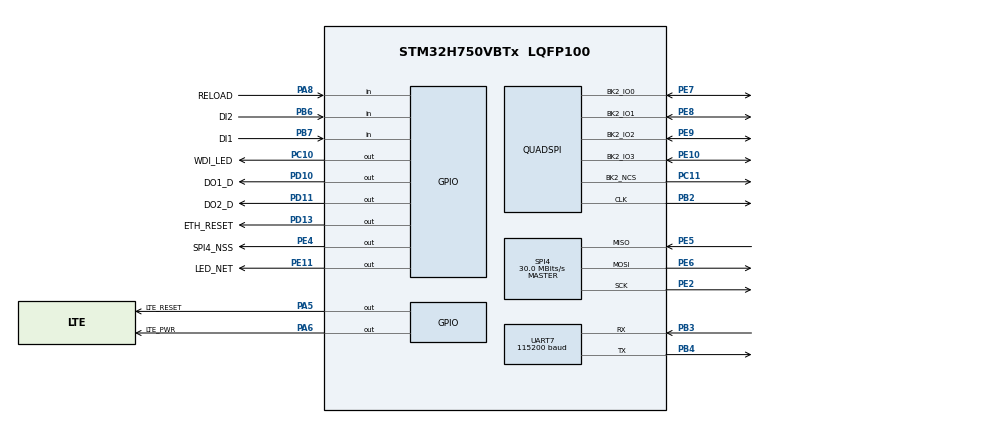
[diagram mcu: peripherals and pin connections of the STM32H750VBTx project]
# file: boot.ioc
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CORTEX_M7.AccessPermission_S-Cortex_Memory_Protection_Unit_Region1_Settings_S=MPU_REGION_PRIV_RO_URO
CORTEX_M7.BaseAddress_S-Cortex_Memory_Protection_Unit_Region1_Settings_S=0x90000000
CORTEX_M7.DisableExec_S-Cortex_Memory_Protection_Unit_Region1_Settings_S=MPU_INSTRUCTION_ACCESS_ENABLE
CORTEX_M7.Enable_S-Cortex_Memory_Protection_Unit_Region1_Settings_S=MPU_REGION_ENABLE
CORTEX_M7.IsBufferable_S-Cortex_Memory_Protection_Unit_Region1_Settings_S=MPU_ACCESS_NOT_BUFFERABLE
CORTEX_M7.IsCacheable_S-Cortex_Memory_Protection_Unit_Region1_Settings_S=MPU_ACCESS_CACHEABLE
CORTEX_M7.IsShareable_S-Cortex_Memory_Protection_Unit_Region1_Settings_S=MPU_ACCESS_NOT_SHAREABLE
CORTEX_M7.MPU_Control=MPU_PRIVILEGED_DEFAULT
CORTEX_M7.Size_S-Cortex_Memory_Protection_Unit_Region1_Settings_S=MPU_REGION_SIZE_4MB
CORTEX_M7.SubRegionDisable_S-Cortex_Memory_Protection_Unit_Region1_Settings_S=0x0
CORTEX_M7.TypeExtField_S-Cortex_Memory_Protection_Unit_Region1_Settings_S=MPU_TEX_LEVEL0
CORTEX_M7.default_mode_Activation=1
IWDG1.Prescaler=IWDG_PRESCALER_32
IWDG1.Reload=1600
Mcu.Family=STM32H7
Mcu.Name=STM32H750VBTx
Mcu.Package=LQFP100
NVIC.PriorityGroup=NVIC_PRIORITYGROUP_4
PA13\ (JTMS/SWDIO).Mode=Serial_Wire
PA13\ (JTMS/SWDIO).Signal=DEBUG_JTMS-SWDIO
PA14\ (JTCK/SWCLK).Mode=Serial_Wire
PA14\ (JTCK/SWCLK).Signal=DEBUG_JTCK-SWCLK
PA5.GPIO_Label=LTE_RESET
PA5.PinState=GPIO_PIN_RESET
PA5.Signal=GPIO_Output
PA6.GPIO_Label=LTE_PWR
PA6.PinState=GPIO_PIN_RESET
PA6.Signal=GPIO_Output
PA8.GPIO_Label=RELOAD
PA8.GPIO_PuPd=GPIO_PULLUP
PA8.Signal=GPIO_Input
PB2.GPIO_Speed=GPIO_SPEED_FREQ_VERY_HIGH
PB2.Mode=Single Bank 2
PB2.Signal=QUADSPI_CLK
PB3\ (JTDO/TRACESWO).GPIO_Speed=GPIO_SPEED_FREQ_HIGH
PB3\ (JTDO/TRACESWO).Mode=Asynchronous
PB3\ (JTDO/TRACESWO).Signal=UART7_RX
PB4\ (NJTRST).GPIO_Speed=GPIO_SPEED_FREQ_HIGH
PB4\ (NJTRST).Mode=Asynchronous
PB4\ (NJTRST).Signal=UART7_TX
PB6.GPIO_Label=DI2
PB6.Signal=GPIO_Input
PB7.GPIO_Label=DI1
PB7.Signal=GPIO_Input
PC10.GPIO_Label=WDI_LED
PC10.PinState=GPIO_PIN_RESET
PC10.Signal=GPIO_Output
PC11.GPIO_Speed=GPIO_SPEED_FREQ_VERY_HIGH
PC11.Mode=Single Bank 2
PC11.Signal=QUADSPI_BK2_NCS
PD10.GPIO_Label=DO1_D
PD10.PinState=GPIO_PIN_RESET
PD10.Signal=GPIO_Output
PD11.GPIO_Label=DO2_D
PD11.PinState=GPIO_PIN_RESET
PD11.Signal=GPIO_Output
PD13.GPIO_Label=ETH_RESET
PD13.GPIO_Speed=GPIO_SPEED_FREQ_VERY_HIGH
PD13.PinState=GPIO_PIN_RESET
PD13.Signal=GPIO_Output
PE10.GPIO_Speed=GPIO_SPEED_FREQ_VERY_HIGH
PE10.Mode=Single Bank 2
PE10.Signal=QUADSPI_BK2_IO3
PE11.GPIO_Label=LED_NET
PE11.PinState=GPIO_PIN_RESET
PE11.Signal=GPIO_Output
PE2.GPIO_Speed=GPIO_SPEED_FREQ_VERY_HIGH
PE2.Mode=Full_Duplex_Master
PE2.Signal=SPI4_SCK
PE4.GPIO_Label=SPI4_NSS
PE4.GPIO_Speed=GPIO_SPEED_FREQ_VERY_HIGH
PE4.PinState=GPIO_PIN_SET
PE4.Signal=GPIO_Output
PE5.GPIO_Speed=GPIO_SPEED_FREQ_VERY_HIGH
PE5.Mode=Full_Duplex_Master
PE5.Signal=SPI4_MISO
PE6.GPIO_Speed=GPIO_SPEED_FREQ_VERY_HIGH
PE6.Mode=Full_Duplex_Master
PE6.Signal=SPI4_MOSI
PE7.GPIO_Speed=GPIO_SPEED_FREQ_VERY_HIGH
PE7.Mode=Single Bank 2
PE7.Signal=QUADSPI_BK2_IO0
PE8.GPIO_Speed=GPIO_SPEED_FREQ_VERY_HIGH
PE8.Mode=Single Bank 2
PE8.Signal=QUADSPI_BK2_IO1
PE9.GPIO_Speed=GPIO_SPEED_FREQ_VERY_HIGH
PE9.Mode=Single Bank 2
PE9.Signal=QUADSPI_BK2_IO2
PH0-OSC_IN\ (PH0).Mode=HSE-External-Oscillator
PH0-OSC_IN\ (PH0).Signal=RCC_OSC_IN
PH1-OSC_OUT\ (PH1).Mode=HSE-External-Oscillator
PH1-OSC_OUT\ (PH1).Signal=RCC_OSC_OUT
ProjectManager.HeapSize=0x0
ProjectManager.StackSize=0x1000
ProjectManager.TargetToolchain=CMake
QUADSPI.ChipSelectHighTime=QSPI_CS_HIGH_TIME_2_CYCLE
QUADSPI.ClockPrescaler=1
QUADSPI.DualFlash=QSPI_DUALFLASH_DISABLE
QUADSPI.FifoThreshold=4
QUADSPI.FlashSize=22
QUADSPI.SampleShifting=QSPI_SAMPLE_SHIFTING_HALFCYCLE
RCC.ADCFreq_Value=50390625
RCC.APB1Freq_Value=120000000
RCC.APB2Freq_Value=120000000
RCC.APB3Freq_Value=120000000
RCC.APB4Freq_Value=120000000
RCC.CortexFreq_Value=480000000
RCC.D1CPRE=RCC_SYSCLK_DIV1
RCC.D1PPRE=RCC_APB3_DIV2
RCC.D2PPRE1=RCC_APB1_DIV2
RCC.D2PPRE2=RCC_APB2_DIV2
RCC.D3PPRE=RCC_APB4_DIV2
RCC.DIVM1=5
RCC.DIVN1=192
RCC.DIVP1=2
RCC.DIVQ1=6
RCC.DIVR1=2
RCC.HCLKFreq_Value=240000000
RCC.HPRE=RCC_HCLK_DIV2
RCC.HSE_VALUE=25000000
RCC.PLLSourceVirtual=RCC_PLLSOURCE_HSE
RCC.PWR_Regulator_Voltage_Scale=PWR_REGULATOR_VOLTAGE_SCALE0
RCC.QSPICLockSelection=RCC_QSPICLKSOURCE_PLL
RCC.SYSCLKFreq_VALUE=480000000
RCC.SYSCLKSource=RCC_SYSCLKSOURCE_PLLCLK
RCC.Spi45ClockSelection=RCC_SPI45CLKSOURCE_D2PCLK1
RCC.SupplySource=PWR_LDO_SUPPLY
RCC.USART234578CLockSelection=RCC_USART234578CLKSOURCE_D2PCLK1
RCC.USBFreq_Value=160000000
SPI4.BaudRatePrescaler=SPI_BAUDRATEPRESCALER_4
SPI4.CalculateBaudRate=30.0 MBits/s
SPI4.DataSize=SPI_DATASIZE_8BIT
SPI4.Direction=SPI_DIRECTION_2LINES
SPI4.MasterKeepIOState=SPI_MASTER_KEEP_IO_STATE_ENABLE
SPI4.MasterReceiverAutoSusp=SPI_MASTER_RX_AUTOSUSP_ENABLE
SPI4.Mode=SPI_MODE_MASTER
SPI4.VirtualType=VM_MASTER
UART7.BaudRate=115200
UART7.VirtualMode=VM_ASYNC
VP_IWDG1_VS_IWDG.Mode=IWDG_Activate
VP_MEMORYMAP_VS_MEMORYMAP.Mode=CurAppReg
board=custom

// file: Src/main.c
/* USER CODE BEGIN Header */
/**
  ******************************************************************************
  * @file           : main.c
  * @brief          : Main program body
  ******************************************************************************
  * @attention
  *
  * Copyright (c) 2026 STMicroelectronics.
  * All rights reserved.
  *
  * This software is licensed under terms that can be found in the LICENSE file
  * in the root directory of this software component.
  * If no LICENSE file comes with this software, it is provided AS-IS.
  *
  ******************************************************************************
  */
/* USER CODE END Header */
#include "main.h"
#include "iwdg.h"
#include "memorymap.h"
#include "quadspi.h"
#include "spi.h"
#include "usart.h"
#include "gpio.h"

/* USER CODE BEGIN Includes */
#include "boot.h"
/* USER CODE END Includes */

void SystemClock_Config(void);
static void MPU_Config(void);

int main(void)
{

  /* USER CODE BEGIN 1 */
  boot_early();
  /* USER CODE END 1 */

  /* MPU Configuration--------------------------------------------------------*/
  MPU_Config();

  /* MCU Configuration--------------------------------------------------------*/

  /* Reset of all peripherals, Initializes the Flash interface and the Systick. */
  HAL_Init();

  /* Configure the system clock */
  SystemClock_Config();

  /* Initialize all configured peripherals */
  MX_GPIO_Init();
  MX_IWDG1_Init();
  MX_QUADSPI_Init();
  MX_UART7_Init();
  MX_SPI4_Init();
  /* USER CODE BEGIN 2 */
  boot_main();
  /* USER CODE END 2 */

  /* Infinite loop */
  while (1)
  {

  }
}

void SystemClock_Config(void)
{
  RCC_OscInitTypeDef RCC_OscInitStruct = {0};
  RCC_ClkInitTypeDef RCC_ClkInitStruct = {0};

  /** Supply configuration update enable
  */
  HAL_PWREx_ConfigSupply(PWR_LDO_SUPPLY);

  /** Configure the main internal regulator output voltage
  */
  __HAL_PWR_VOLTAGESCALING_CONFIG(PWR_REGULATOR_VOLTAGE_SCALE0);

  while(!__HAL_PWR_GET_FLAG(PWR_FLAG_VOSRDY)) {}

  /** Initializes the RCC Oscillators according to the specified parameters
  * in the RCC_OscInitTypeDef structure.
  */
  RCC_OscInitStruct.OscillatorType = RCC_OSCILLATORTYPE_LSI|RCC_OSCILLATORTYPE_HSE;
  RCC_OscInitStruct.HSEState = RCC_HSE_ON;
  RCC_OscInitStruct.LSIState = RCC_LSI_ON;
  RCC_OscInitStruct.PLL.PLLState = RCC_PLL_ON;
  RCC_OscInitStruct.PLL.PLLSource = RCC_PLLSOURCE_HSE;
  RCC_OscInitStruct.PLL.PLLM = 5;
  RCC_OscInitStruct.PLL.PLLN = 192;
  RCC_OscInitStruct.PLL.PLLP = 2;
  RCC_OscInitStruct.PLL.PLLQ = 6;
  RCC_OscInitStruct.PLL.PLLR = 2;
  RCC_OscInitStruct.PLL.PLLRGE = RCC_PLL1VCIRANGE_2;
  RCC_OscInitStruct.PLL.PLLVCOSEL = RCC_PLL1VCOWIDE;
  RCC_OscInitStruct.PLL.PLLFRACN = 0;
  if (HAL_RCC_OscConfig(&RCC_OscInitStruct) != HAL_OK)
  {
    Error_Handler();
  }

  /** Initializes the CPU, AHB and APB buses clocks
  */
  RCC_ClkInitStruct.ClockType = RCC_CLOCKTYPE_HCLK|RCC_CLOCKTYPE_SYSCLK
                              |RCC_CLOCKTYPE_PCLK1|RCC_CLOCKTYPE_PCLK2
                              |RCC_CLOCKTYPE_D3PCLK1|RCC_CLOCKTYPE_D1PCLK1;
  RCC_ClkInitStruct.SYSCLKSource = RCC_SYSCLKSOURCE_PLLCLK;
  RCC_ClkInitStruct.SYSCLKDivider = RCC_SYSCLK_DIV1;
  RCC_ClkInitStruct.AHBCLKDivider = RCC_HCLK_DIV2;
  RCC_ClkInitStruct.APB3CLKDivider = RCC_APB3_DIV2;
  RCC_ClkInitStruct.APB1CLKDivider = RCC_APB1_DIV2;
  RCC_ClkInitStruct.APB2CLKDivider = RCC_APB2_DIV2;
  RCC_ClkInitStruct.APB4CLKDivider = RCC_APB4_DIV2;

  if (HAL_RCC_ClockConfig(&RCC_ClkInitStruct, FLASH_LATENCY_4) != HAL_OK)
  {
    Error_Handler();
  }
}

 /* MPU Configuration */

void MPU_Config(void)
{
  MPU_Region_InitTypeDef MPU_InitStruct = {0};

  /* Disables the MPU */
  HAL_MPU_Disable();

  /** Initializes and configures the Region and the memory to be protected
  */
  MPU_InitStruct.Enable = MPU_REGION_ENABLE;
  MPU_InitStruct.Number = MPU_REGION_NUMBER0;
  MPU_InitStruct.BaseAddress = 0x0;
  MPU_InitStruct.Size = MPU_REGION_SIZE_4GB;
  MPU_InitStruct.SubRegionDisable = 0x87;
  MPU_InitStruct.TypeExtField = MPU_TEX_LEVEL0;
  MPU_InitStruct.AccessPermission = MPU_REGION_NO_ACCESS;
  MPU_InitStruct.DisableExec = MPU_INSTRUCTION_ACCESS_DISABLE;
  MPU_InitStruct.IsShareable = MPU_ACCESS_SHAREABLE;
  MPU_InitStruct.IsCacheable = MPU_ACCESS_NOT_CACHEABLE;
  MPU_InitStruct.IsBufferable = MPU_ACCESS_NOT_BUFFERABLE;

  HAL_MPU_ConfigRegion(&MPU_InitStruct);

  /** Initializes and configures the Region and the memory to be protected
  */
  MPU_InitStruct.Number = MPU_REGION_NUMBER1;
  MPU_InitStruct.BaseAddress = 0x90000000;
  MPU_InitStruct.Size = MPU_REGION_SIZE_4MB;
  MPU_InitStruct.SubRegionDisable = 0x0;
  MPU_InitStruct.AccessPermission = MPU_REGION_PRIV_RO_URO;
  MPU_InitStruct.DisableExec = MPU_INSTRUCTION_ACCESS_ENABLE;
  MPU_InitStruct.IsShareable = MPU_ACCESS_NOT_SHAREABLE;
  MPU_InitStruct.IsCacheable = MPU_ACCESS_CACHEABLE;

  HAL_MPU_ConfigRegion(&MPU_InitStruct);
  /* Enables the MPU */
  HAL_MPU_Enable(MPU_PRIVILEGED_DEFAULT);

}

void Error_Handler(void)
{
  __disable_irq();
  while (1)
  {
  }
}
